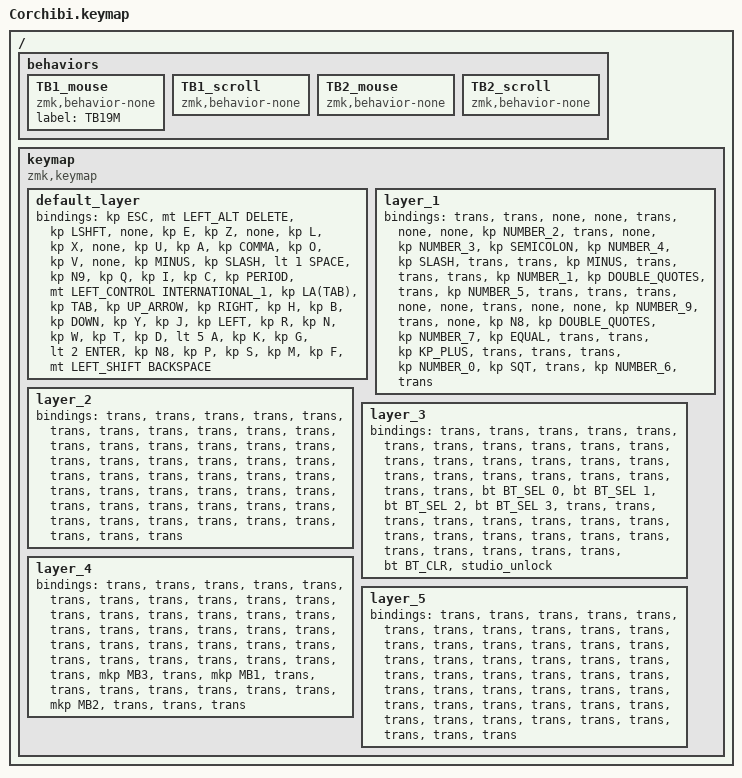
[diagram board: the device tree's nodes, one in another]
#include <dt-bindings/zmk/mouse.h>
#include <behaviors.dtsi>
#include <dt-bindings/zmk/bt.h>
#include <dt-bindings/zmk/keys.h>
#include <dt-bindings/zmk/pointing.h>

/ {
    behaviors {
        TB1_mouse: TB1_mouse {
            compatible = "zmk,behavior-none";
            label = "TB19M";
            #binding-cells = <0>;
        };

        TB1_scroll: TB1_scroll {
            compatible = "zmk,behavior-none";
            #binding-cells = <0>;
        };

        TB2_mouse: TB2_mouse {
            compatible = "zmk,behavior-none";
            #binding-cells = <0>;
        };

        TB2_scroll: TB2_scroll {
            compatible = "zmk,behavior-none";
            #binding-cells = <0>;
        };
    };

    keymap {
        compatible = "zmk,keymap";

        default_layer {
            bindings = <
&kp ESC  &mt LEFT_ALT DELETE  &kp LSHFT  &none  &kp E  &kp Z  &none  &kp L  &kp X  &none  &kp U  &kp A  &kp COMMA  &kp O  &kp V  &none  &kp MINUS  &kp SLASH  &lt 1 SPACE  &kp N9  &kp Q  &kp I  &kp C  &kp PERIOD  &mt LEFT_CONTROL INTERNATIONAL_1  &kp LA(TAB)  &kp TAB  &kp UP_ARROW  &kp RIGHT  &kp H  &kp B  &kp DOWN  &kp Y  &kp J  &kp LEFT  &kp R  &kp N  &kp W  &kp T  &kp D  &lt 5 A  &kp K  &kp G  &lt 2 ENTER  &kp N8  &kp P  &kp S  &kp M  &kp F  &mt LEFT_SHIFT BACKSPACE
            >;
        };

        layer_1 {
            bindings = <
&trans  &trans  &none  &none  &trans  &none  &none  &kp NUMBER_2  &trans  &none  &kp NUMBER_3  &kp SEMICOLON  &kp NUMBER_4  &kp SLASH  &trans  &trans  &kp MINUS  &trans  &trans  &trans  &kp NUMBER_1  &kp DOUBLE_QUOTES  &trans  &kp NUMBER_5  &trans  &trans  &trans  &none  &none  &trans  &none  &none  &kp NUMBER_9  &trans  &none  &kp N8  &kp DOUBLE_QUOTES  &kp NUMBER_7  &kp EQUAL  &trans  &trans  &kp KP_PLUS  &trans  &trans  &trans  &kp NUMBER_0  &kp SQT  &trans  &kp NUMBER_6  &trans
            >;
        };

        layer_2 {
            bindings = <
&trans  &trans  &trans  &trans  &trans  &trans  &trans  &trans  &trans  &trans  &trans  &trans  &trans  &trans  &trans  &trans  &trans  &trans  &trans  &trans  &trans  &trans  &trans  &trans  &trans  &trans  &trans  &trans  &trans  &trans  &trans  &trans  &trans  &trans  &trans  &trans  &trans  &trans  &trans  &trans  &trans  &trans  &trans  &trans  &trans  &trans  &trans  &trans  &trans  &trans
            >;
        };

        layer_3 {
            bindings = <
&trans  &trans  &trans  &trans  &trans  &trans  &trans  &trans  &trans  &trans  &trans  &trans  &trans  &trans  &trans  &trans  &trans  &trans  &trans  &trans  &trans  &trans  &trans  &trans  &trans  &bt BT_SEL 0  &bt BT_SEL 1  &bt BT_SEL 2  &bt BT_SEL 3  &trans  &trans  &trans  &trans  &trans  &trans  &trans  &trans  &trans  &trans  &trans  &trans  &trans  &trans  &trans  &trans  &trans  &trans  &trans  &bt BT_CLR  &studio_unlock
            >;
        };

        layer_4 {
            bindings = <
&trans  &trans  &trans  &trans  &trans  &trans  &trans  &trans  &trans  &trans  &trans  &trans  &trans  &trans  &trans  &trans  &trans  &trans  &trans  &trans  &trans  &trans  &trans  &trans  &trans  &trans  &trans  &trans  &trans  &trans  &trans  &trans  &trans  &trans  &trans  &trans  &mkp MB3  &trans  &mkp MB1  &trans  &trans  &trans  &trans  &trans  &trans  &trans  &mkp MB2  &trans  &trans  &trans
            >;
        };

        layer_5 {
            bindings = <
&trans  &trans  &trans  &trans  &trans  &trans  &trans  &trans  &trans  &trans  &trans  &trans  &trans  &trans  &trans  &trans  &trans  &trans  &trans  &trans  &trans  &trans  &trans  &trans  &trans  &trans  &trans  &trans  &trans  &trans  &trans  &trans  &trans  &trans  &trans  &trans  &trans  &trans  &trans  &trans  &trans  &trans  &trans  &trans  &trans  &trans  &trans  &trans  &trans  &trans
            >;
        };
    };
};

// force trigger build
// apply DYA studio fixes
// fix central role and remove advertising config
// fix missing BLE central role
// slim down R config and fix endpoints
// bypass compiler strict warnings for auto_mouse_layer
// fix endpoint count by forcing central role
// remove invalid cmake configs
// remove undefined moNa2 configs
